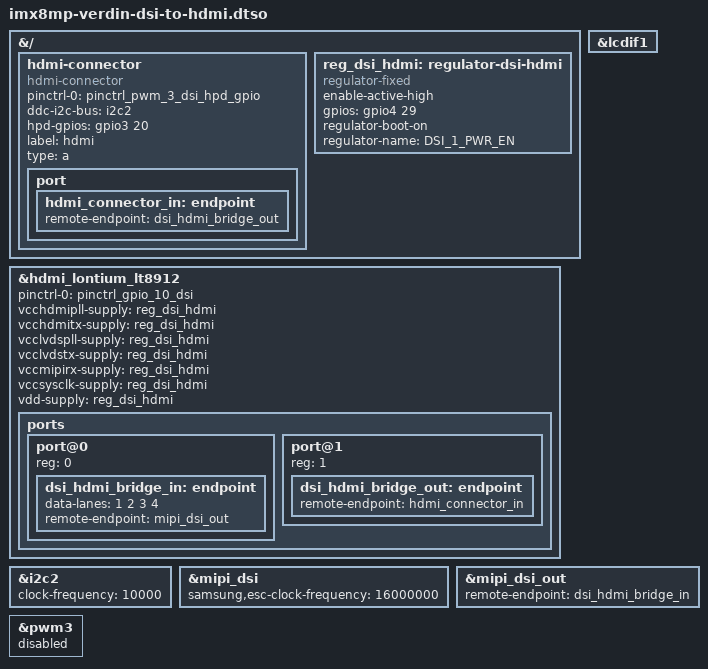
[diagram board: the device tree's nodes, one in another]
// SPDX-License-Identifier: GPL-2.0-only OR MIT
/*
 * Copyright (c) Toradex
 *
 * Toradex DSI to HDMI Adapter on Verdin DSI_1.
 *
 * https://developer.toradex.com/hardware/accessories/add-ons/dsi-hdmi-adapter
 */

/dts-v1/;
/plugin/;

#include <dt-bindings/gpio/gpio.h>

&{/} {
	hdmi-connector {
		compatible = "hdmi-connector";
		pinctrl-names = "default";
		pinctrl-0 = <&pinctrl_pwm_3_dsi_hpd_gpio>;
		ddc-i2c-bus = <&i2c2>;
		/* Verdin PWM_3_DSI (SODIMM 19) - HPD */
		hpd-gpios = <&gpio3 20 GPIO_ACTIVE_HIGH>;
		label = "hdmi";
		type = "a";

		port {
			hdmi_connector_in: endpoint {
				remote-endpoint = <&dsi_hdmi_bridge_out>;
			};
		};
	};

	reg_dsi_hdmi: regulator-dsi-hdmi {
		compatible = "regulator-fixed";
		enable-active-high;
		/* Verdin CTRL_SLEEP_MOCI# (SODIMM 256) */
		gpios = <&gpio4 29 GPIO_ACTIVE_HIGH>;
		regulator-boot-on;
		regulator-name = "DSI_1_PWR_EN";
	};
};

&hdmi_lontium_lt8912 {
	pinctrl-0 = <&pinctrl_gpio_10_dsi>;
	vcchdmipll-supply = <&reg_dsi_hdmi>;
	vcchdmitx-supply = <&reg_dsi_hdmi>;
	vcclvdspll-supply = <&reg_dsi_hdmi>;
	vcclvdstx-supply = <&reg_dsi_hdmi>;
	vccmipirx-supply = <&reg_dsi_hdmi>;
	vccsysclk-supply = <&reg_dsi_hdmi>;
	vdd-supply = <&reg_dsi_hdmi>;

	status = "okay";

	ports {
		#address-cells = <1>;
		#size-cells = <0>;

		port@0 {
			reg = <0>;

			dsi_hdmi_bridge_in: endpoint {
				data-lanes = <1 2 3 4>;
				remote-endpoint = <&mipi_dsi_out>;
			};
		};

		port@1 {
			reg = <1>;

			dsi_hdmi_bridge_out: endpoint {
				remote-endpoint = <&hdmi_connector_in>;
			};
		};
	};
};

/* Verdin I2C_2_DSI */
&i2c2 {
	clock-frequency = <10000>;

	status = "okay";
};

&lcdif1 {
	status = "okay";
};

&mipi_dsi {
	samsung,esc-clock-frequency = <16000000>;

	status = "okay";
};

&mipi_dsi_out {
	remote-endpoint = <&dsi_hdmi_bridge_in>;
};

/* Verdin PWM_3_DSI (SODIMM 19) repurposed as HDMI HPD GPIO */
&pwm3 {
	status = "disabled";
};
